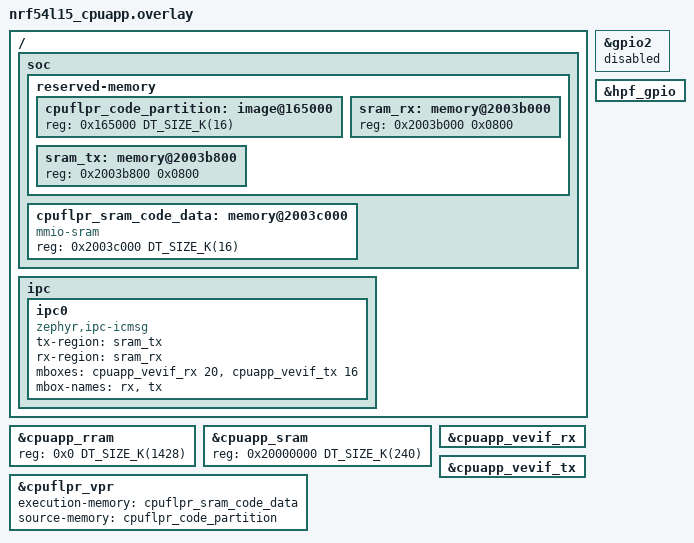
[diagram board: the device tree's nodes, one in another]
/*
 * Copyright (c) 2024 Nordic Semiconductor ASA
 *
 * SPDX-License-Identifier: LicenseRef-Nordic-5-Clause
 */

#include "../../hpf-gpio-app.overlay"

/ {
	soc {
		reserved-memory {
			#address-cells = <1>;
			#size-cells = <1>;

			cpuflpr_code_partition: image@165000 {
				reg = <0x165000 DT_SIZE_K(16)>;
			};

			sram_rx: memory@2003b000 {
				reg = <0x2003b000 0x0800>;
			};

			sram_tx: memory@2003b800 {
				reg = <0x2003b800 0x0800>;
			};
		};


		cpuflpr_sram_code_data: memory@2003c000 {
			compatible = "mmio-sram";
			reg = <0x2003c000 DT_SIZE_K(16)>;
			#address-cells = <1>;
			#size-cells = <1>;
			ranges = <0x0 0x2003c000 0x4000>;
		};
	};

	ipc {
		ipc0: ipc0 {
			compatible = "zephyr,ipc-icmsg";
			tx-region = <&sram_tx>;
			rx-region = <&sram_rx>;
			mboxes = <&cpuapp_vevif_rx 20>, <&cpuapp_vevif_tx 16>;
			mbox-names = "rx", "tx";
			status = "okay";
		};
	};
};

&cpuapp_rram {
	reg = <0x0 DT_SIZE_K(1428)>;
};

&cpuapp_sram {
	reg = <0x20000000 DT_SIZE_K(240)>;
	ranges = <0x0 0x20000000 0x3c000>;
};

&cpuflpr_vpr {
	execution-memory = <&cpuflpr_sram_code_data>;
	source-memory = <&cpuflpr_code_partition>;
};

&gpio2 {
	status = "disabled";
};

&cpuapp_vevif_rx {
	status = "okay";
};

&cpuapp_vevif_tx {
	status = "okay";
};

&hpf_gpio {
	status = "okay";
};
